AUTOSAR XML (schema 4-0-3)
standard types defined: Boolean, UInt16, UInt32, UInt8
package /AUTOSAR_Platform/DataConstrs
  range DC_Boolean: raw 0..1
  range DC_UInt16: raw 0..65535
  range DC_UInt8: raw 0..255
package /PATAC/MSM/ComponentTypes
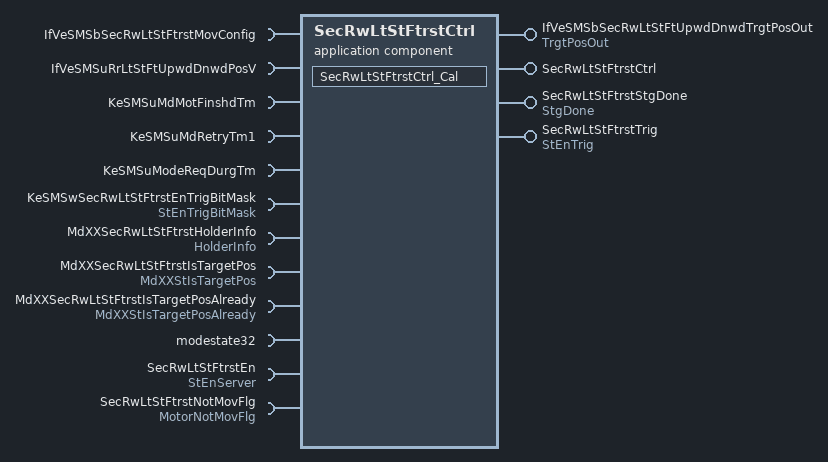
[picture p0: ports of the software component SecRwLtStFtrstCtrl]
  application sw component type SecRwLtStFtrstCtrl
    4 x provide port:
      IfVeSMSbSecRwLtStFtUpwdDnwdTrgtPosOut: nonqueued-sender-com-spec{data-element=TrgtPosOut/Val, init-value=0}, provided-interface=TrgtPosOut
      SecRwLtStFtrstCtrl: server-com-spec{operation=Cal, queue-length=1}, provided-interface=SecRwLtStFtrstCtrl
      SecRwLtStFtrstStgDone: nonqueued-sender-com-spec{data-element=StgDone/Val, init-value=0}, provided-interface=StgDone
      SecRwLtStFtrstTrig: nonqueued-sender-com-spec{data-element=StEnTrig/Val, init-value=0}, provided-interface=StEnTrig
    12 x require port:
      IfVeSMSbSecRwLtStFtrstMovConfig: nonqueued-receiver-com-spec{data-element=IfVeSMSbSecRwLtStFtrstMovConfig/Val, filter=data-filter-type=ALWAYS, init-value=0}, required-interface=IfVeSMSbSecRwLtStFtrstMovConfig
      IfVeSMSuRrLtStFtUpwdDnwdPosV: nonqueued-receiver-com-spec{data-element=IfVeSMSuRrLtStFtUpwdDnwdPosV/Val, filter=data-filter-type=ALWAYS, init-value=0}, required-interface=IfVeSMSuRrLtStFtUpwdDnwdPosV
      KeSMSuMdMotFinshdTm: parameter-require-com-spec{init-value=0, parameter=KeSMSuMdMotFinshdTm/Val}, required-interface=KeSMSuMdMotFinshdTm
      KeSMSuMdRetryTm1: parameter-require-com-spec{init-value=0, parameter=KeSMSuMdRetryTm1/Val}, required-interface=KeSMSuMdRetryTm1
      KeSMSuModeReqDurgTm: parameter-require-com-spec{init-value=0, parameter=KeSMSuModeReqDurgTm/Val}, required-interface=KeSMSuModeReqDurgTm
      KeSMSwSecRwLtStFtrstEnTrigBitMask: parameter-require-com-spec{init-value=6153, parameter=StEnTrigBitMask/Val}, required-interface=StEnTrigBitMask
      MdXXSecRwLtStFtrstHolderInfo: nonqueued-receiver-com-spec{data-element=HolderInfo/Val, filter=data-filter-type=ALWAYS, init-value=0}, required-interface=HolderInfo
      MdXXSecRwLtStFtrstIsTargetPos: nonqueued-receiver-com-spec{data-element=MdXXStIsTargetPos/Val, filter=data-filter-type=ALWAYS, init-value=0}, required-interface=MdXXStIsTargetPos
      MdXXSecRwLtStFtrstIsTargetPosAlready: nonqueued-receiver-com-spec{data-element=MdXXStIsTargetPosAlready/Val, filter=data-filter-type=ALWAYS, init-value=0}, required-interface=MdXXStIsTargetPosAlready
      modestate32: nonqueued-receiver-com-spec{data-element=modestate32/Val, filter=data-filter-type=ALWAYS, init-value=0}, required-interface=modestate32
      SecRwLtStFtrstEn: required-com-specs=[Clear, Get, Set], required-interface=StEnServer
      SecRwLtStFtrstNotMovFlg: nonqueued-receiver-com-spec{data-element=MotorNotMovFlg/Val, filter=data-filter-type=ALWAYS, init-value=0}, required-interface=MotorNotMovFlg
    behavior SecRwLtStFtrstCtrl_InternalBehavior
      operation invoked event OIT_SecRwLtStFtrstCtrl_Cal_SecRwLtStFtrstCtrl_Cal: start-on-event=SecRwLtStFtrstCtrl_Cal, operation=SecRwLtStFtrstCtrl.Cal
      runnable SecRwLtStFtrstCtrl_Cal
        data-receive-point-by-arguments:
          7 x access:
            REC_IfVeSMSbSecRwLtStFtrstMovConfig_Val: accessed-variable=IfVeSMSbSecRwLtStFtrstMovConfig.Val
            REC_IfVeSMSuRrLtStFtUpwdDnwdPosV_Val: accessed-variable=IfVeSMSuRrLtStFtUpwdDnwdPosV.Val
            REC_MdXXSecRwLtStFtrstHolderInfo_Val: accessed-variable=MdXXSecRwLtStFtrstHolderInfo.Val
            REC_MdXXSecRwLtStFtrstIsTargetPos_Val: accessed-variable=MdXXSecRwLtStFtrstIsTargetPos.Val
            REC_MdXXSecRwLtStFtrstIsTargetPosAlready_Val: accessed-variable=MdXXSecRwLtStFtrstIsTargetPosAlready.Val
            REC_modestate32_Val: accessed-variable=modestate32.Val
            REC_SecRwLtStFtrstNotMovFlg_Val: accessed-variable=SecRwLtStFtrstNotMovFlg.Val
        data-send-points:
          access SEND_IfVeSMSbSecRwLtStFtUpwdDnwdTrgtPosOut_Val: accessed-variable=IfVeSMSbSecRwLtStFtUpwdDnwdTrgtPosOut.Val
          access SEND_SecRwLtStFtrstStgDone_Val: accessed-variable=SecRwLtStFtrstStgDone.Val
          access SEND_SecRwLtStFtrstTrig_Val: accessed-variable=SecRwLtStFtrstTrig.Val
        4 x parameter access:
          PA_KeSMSuMdMotFinshdTm_Val: accessed-parameter=KeSMSuMdMotFinshdTm.Val
          PA_KeSMSuMdRetryTm1_Val: accessed-parameter=KeSMSuMdRetryTm1.Val
          PA_KeSMSuModeReqDurgTm_Val: accessed-parameter=KeSMSuModeReqDurgTm.Val
          PA_KeSMSwSecRwLtStFtrstEnTrigBitMask_Val: accessed-parameter=KeSMSwSecRwLtStFtrstEnTrigBitMask.Val
        sync call SC_SecRwLtStFtrstEn_Get: operation=SecRwLtStFtrstEn.Get, timeout=0
  swc implementation SecRwLtStFtrstCtrl_Implementation: behavior=SecRwLtStFtrstCtrl_InternalBehavior
    code-descriptors:
      code Default: artifact-descriptors=autosar-engineering-object={short-label=Default, category=SWSRC}
package /PATAC/MSM/ModeAdjust/CalPortInterface
  parameter interface KeSMSuMdMotFinshdTm
    parameter data prototype Val: sw-calibration-access=READ-WRITE, type=UInt16
  parameter interface KeSMSuModeReqDurgTm
    parameter data prototype Val: sw-calibration-access=READ-WRITE, type=UInt16
  parameter interface StEnTrigBitMask
    parameter data prototype Val: sw-calibration-access=READ-WRITE, type=UInt32
package /PATAC/MSM/ModeAdjust/PortInterface
  client server interface SecRwLtStFtrstCtrl
    operation Cal
  client server interface StEnServer
    operation Clear
      arg data: type=UInt8, direction=IN, server-argument-impl-policy=USE-ARGUMENT-TYPE
    operation Get
      arg data: type=UInt32, direction=OUT, server-argument-impl-policy=USE-ARGUMENT-TYPE
    operation Set
      arg data: type=UInt8, direction=IN, server-argument-impl-policy=USE-ARGUMENT-TYPE
  9 x sender receiver interface:
    HolderInfo: invalidation-policy{data-element=HolderInfo/Val, handle-invalid=DONT-INVALIDATE}
      data Val: type=UInt32
    IfVeSMSbSecRwLtStFtrstMovConfig: invalidation-policy{data-element=IfVeSMSbSecRwLtStFtrstMovConfig/Val, handle-invalid=DONT-INVALIDATE}
      data Val: type=Boolean
    MdXXStIsTargetPos: invalidation-policy{data-element=MdXXStIsTargetPos/Val, handle-invalid=DONT-INVALIDATE}
      data Val: type=UInt32
    MdXXStIsTargetPosAlready: invalidation-policy{data-element=MdXXStIsTargetPosAlready/Val, handle-invalid=DONT-INVALIDATE}
      data Val: type=UInt32
    modestate32: invalidation-policy{data-element=modestate32/Val, handle-invalid=DONT-INVALIDATE}
      data Val: type=UInt32
    MotorNotMovFlg: invalidation-policy{data-element=MotorNotMovFlg/Val, handle-invalid=DONT-INVALIDATE}
      data Val: type=Boolean
    StEnTrig: invalidation-policy{data-element=StEnTrig/Val, handle-invalid=DONT-INVALIDATE}
      data Val: type=Boolean
    StgDone: invalidation-policy{data-element=StgDone/Val, handle-invalid=DONT-INVALIDATE}
      data Val: type=Boolean
    TrgtPosOut: invalidation-policy{data-element=TrgtPosOut/Val, handle-invalid=DONT-INVALIDATE}
      data Val: type=Boolean
package /PATAC/MSM/PortInterfaces
  parameter interface KeSMSuMdRetryTm1
    parameter data prototype Val: sw-calibration-access=READ-WRITE, type=UInt8
  sender receiver interface IfVeSMSuRrLtStFtUpwdDnwdPosV: invalidation-policy{data-element=IfVeSMSuRrLtStFtUpwdDnwdPosV/Val, handle-invalid=DONT-INVALIDATE}
    data Val: type=Boolean
